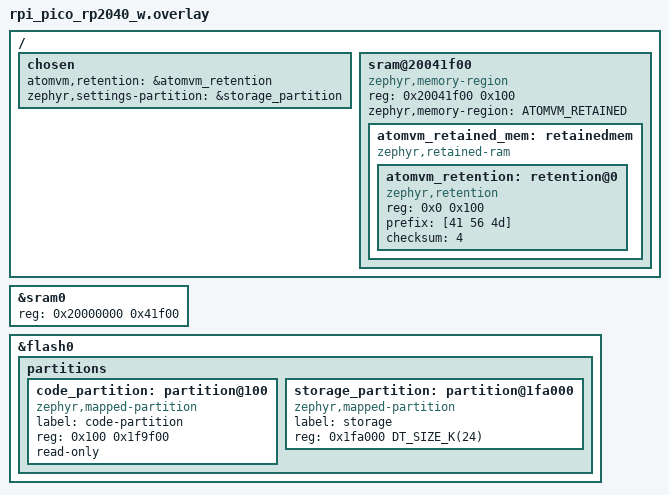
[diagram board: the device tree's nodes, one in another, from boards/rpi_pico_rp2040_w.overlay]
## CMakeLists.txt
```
#
# This file is part of AtomVM.
#
# Copyright 2023 Winford (Uncle Grumpy) <winford@object.stream>
#
# Licensed under the Apache License, Version 2.0 (the "License");
# you may not use this file except in compliance with the License.
# You may obtain a copy of the License at
#
#    http://www.apache.org/licenses/LICENSE-2.0
#
# Unless required by applicable law or agreed to in writing, software
# distributed under the License is distributed on an "AS IS" BASIS,
# WITHOUT WARRANTIES OR CONDITIONS OF ANY KIND, either express or implied.
# See the License for the specific language governing permissions and
# limitations under the License.
#
# SPDX-License-Identifier: Apache-2.0 OR LGPL-2.1-or-later
#

cmake_minimum_required (VERSION 3.20)
set(CMAKE_C_STANDARD_REQUIRED YES)
set(CMAKE_CXX_STANDARD_REQUIRED YES)

# Enforce to disable any compiler-specific extensions
set(CMAKE_C_EXTENSIONS NO)
set(CMAKE_CXX_EXTENSIONS NO)
set(C_STANDARD_REQUIRED YES)
set_property(GLOBAL PROPERTY C_STANDARD_REQUIRED TRUE)
set_property(GLOBAL PROPERTY CSTD iso9899:2011)
set_property(GLOBAL PROPERTY C_STANDARD iso9899:2011)

find_package(Zephyr REQUIRED HINTS $ENV{ZEPHYR_BASE})
project(AtomVM LANGUAGES C)

if (NOT BOARD)
    message(FATAL_ERROR "No BOARD specified for device config generator")
endif ()

list(APPEND CMAKE_MODULE_PATH "${CMAKE_CURRENT_SOURCE_DIR}/../../../CMakeModules")
set(CMAKE_RUNTIME_OUTPUT_DIRECTORY ${CMAKE_BINARY_DIR})

# Options that make sense for this platform
option(AVM_USE_32BIT_FLOAT "Use 32 bit floats." ON)
option(AVM_VERBOSE_ABORT "Print module and line number on VM abort" OFF)
option(AVM_CREATE_STACKTRACES "Create stacktraces" ON)
option(AVM_NEWLIB_NANO "Use 'nano' newlib. Saves 46kB, no `long long` support" OFF)
option(AVM_LOG_DISABLE "Disable log output" OFF)
option(AVM_ENABLE_LOG_COLOR "Use color log output" OFF)
option(AVM_ENABLE_LOG_LINES "Include source and line info for all enabled levels" OFF)
option(AVM_CONFIG_REBOOT_ON_NOT_OK "Reboot when application exits with non 'ok' return" OFF)
option(AVM_DISABLE_GPIO_NIFS "Disable GPIO nifs (input and output)" OFF)
option(AVM_DISABLE_GPIO_PORT_DRIVER "Disable GPIO 'port' driver (input, output, and interrupts)" OFF)

set(AVM_DISABLE_SMP ON CACHE BOOL "Disable SMP" FORCE)
set(AVM_DISABLE_TASK_DRIVER OFF CACHE BOOL "Disable Task Driver" FORCE)
zephyr_library_compile_definitions(AVM_NO_SMP)
add_compile_definitions(AVM_NO_SMP)
add_compile_definitions(AVM_NO_JIT)
add_compile_definitions(_GNU_SOURCE)
add_compile_definitions(_POSIX_C_SOURCE=200809L)
if (NOT AVM_DISABLE_TASK_DRIVER)
    add_compile_definitions(AVM_TASK_DRIVER_ENABLED)
endif()
if (CONFIG_NET_SOCKETS)
    add_compile_definitions(OTP_SOCKET_BSD=1)
endif()

set(HAVE_CLOCK_SETTIME ON FORCE)
set(HAVE_PLATFORM_ATOMIC_H ON CACHE BOOL "Platform has platform_atomic.h" FORCE)
if(CONFIG_SOC_FAMILY_ESPRESSIF_ESP32 AND CONFIG_RISCV)
    # Espressif RISC-V targets such as ESP32-C3 can pass libAtomVM's C11
    # atomic compile check but fail to link __atomic_fetch_* helpers. Use
    # Zephyr's platform atomic shim instead of advertising HAVE_ATOMIC.
    set(ATOMIC_POINTER_LOCK_FREE_IS_TWO FALSE CACHE INTERNAL "Use Zephyr platform atomics" FORCE)
endif()
set(HAVE_RENAME "" CACHE INTERNAL "Have symbol rename" FORCE)

if (AVM_NEWLIB_NANO)
    set(LINKER_FLAGS "${LINKER_FLAGS} -specs=nano.specs")
    set(AVM_LOG_DISABLE ON FORCE)
endif()

if (AVM_CONFIG_REBOOT_ON_NOT_OK)
    add_compile_definitions(CONFIG_REBOOT_ON_NOT_OK)
endif()

# Configure logging
if (AVM_LOG_DISABLE)
    add_compile_definitions(AVM_LOG_DISABLE)
elseif (AVM_LOG_LEVEL_MAX)
    set(AVM_LOG_LEVEL_MAX ${AVM_LOG_LEVEL_MAX} CACHE STRING "AtomVM max log level")
else()
    set(AVM_LOG_LEVEL_MAX LOG_INFO CACHE STRING "AtomVM max log level")
endif()
if (AVM_LOG_LEVEL_MAX)
    set_property(CACHE AVM_LOG_LEVEL_MAX PROPERTY STRINGS LOG_NONE LOG_ERROR LOG_WARN LOG_INFO LOG_DEBUG)
    add_compile_definitions(AVM_LOG_LEVEL_MAX=${AVM_LOG_LEVEL_MAX})
endif()
if (AVM_ENABLE_LOG_COLOR)
    add_compile_definitions(ENABLE_LOG_COLOR)
endif()
if (AVM_ENABLE_LOG_LINES)
    add_compile_definitions(ENABLE_LOG_LINE_INFO)
endif()

# Configure Drivers
if (AVM_DISABLE_GPIO_NIFS)
    add_compile_definitions(AVM_DISABLE_GPIO_NIFS)
endif()
if (AVM_DISABLE_GPIO_PORT_DRIVER)
    add_compile_definitions(AVM_DISABLE_GPIO_PORT_DRIVER)
endif()

## Include additional compilation flags
#include(cmake/compile-flags.cmake)

set(
    PLATFORM_LIB_SUFFIX
    ${CMAKE_SYSTEM_NAME}-${CMAKE_SYSTEM_PROCESSOR}
)

# Specify output executable
target_sources(app PRIVATE src/main.c)
target_include_directories(app PRIVATE
    ${CMAKE_CURRENT_BINARY_DIR}/libAtomVM
    ${CMAKE_BINARY_DIR}/zephyr/include/generated)

add_subdirectory(src/lib)

target_link_libraries(app PRIVATE libAtomVM${PLATFORM_LIB_SUFFIX})

set_property(TARGET app PROPERTY C_STANDARD 11)

if(CMAKE_COMPILER_IS_GNUCC)
    target_compile_options(app PUBLIC -Wall -Wextra -ggdb)
endif()

set(AVM_PORT_ZEPHYR ON CACHE BOOL "Build for Zephyr" FORCE)
set(AVM_DISABLE_JIT ON CACHE BOOL "Disable JIT" FORCE)
add_subdirectory(../../libAtomVM libAtomVM)
target_include_directories(libAtomVM PUBLIC src/lib)
add_dependencies(libAtomVM zephyr_generated_headers)
add_dependencies(libAtomVM${PLATFORM_LIB_SUFFIX} zephyr_generated_headers)
target_link_libraries(app PUBLIC libAtomVM)

message("----------------------------------------")
message(STATUS "Board       : ${BOARD}")
message("--------Device Configuration Info-------")
message(STATUS "Clock Hz    : ${CONFIG_SYS_CLOCK_HW_CYCLES_PER_SEC}")
message(STATUS "Flash Size  : ${CONFIG_FLASH_SIZE}K")
```

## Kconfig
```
#
# Copyright 2026 Peter M <petermm@gmail.com>
#
# SPDX-License-Identifier: Apache-2.0 OR LGPL-2.1-or-later
#

mainmenu "AtomVM Zephyr Configuration"

source "$(APPLICATION_SOURCE_DIR)/Kconfig.atomvm"
source "Kconfig.zephyr"
```

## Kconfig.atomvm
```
#
# Copyright 2026 Peter M <petermm@gmail.com>
#
# SPDX-License-Identifier: Apache-2.0 OR LGPL-2.1-or-later
#

menu "AtomVM Settings"

config AVM_ENABLE_WIFI
    bool "Enable Wi-Fi and Networking support"
    default y if SOC_WIFI_SUPPORTED
    default n
    imply NETWORKING
    imply NET_L2_ETHERNET
    imply NET_IPV4
    imply NET_DHCPV4
    imply DNS_RESOLVER
    imply NET_TCP
    imply NET_UDP
    imply NET_SOCKETS
    imply SNTP
    imply NET_SOCKETS_SERVICE
    imply NET_CONNECTION_MANAGER
    imply WIFI
    imply NET_L2_WIFI_MGMT
    imply NET_MGMT
    imply NET_MGMT_EVENT
    imply NET_MGMT_EVENT_INFO
    imply EVENTFD
    imply ZVFS
    help
      Enable WiFi networking and socket support in AtomVM.

config AVM_ENABLE_CRYPTO
    bool "Enable Crypto support (MBEDTLS/PSA)"
    default y
    imply MBEDTLS
    imply PSA_CRYPTO
    imply MBEDTLS_HASH_ALL_ENABLED
    imply MBEDTLS_CIPHER_ALL_ENABLED
    imply MBEDTLS_CIPHER
    imply PSA_WANT_ALG_CFB
    imply PSA_WANT_ALG_ECB_NO_PADDING
    imply MBEDTLS_CTR_DRBG_C
    imply MBEDTLS_SSL_PROTO_TLS1_2 if NETWORKING
    imply MBEDTLS_SSL_PROTO_TLS1_3 if NETWORKING
    imply MBEDTLS_SSL_TLS1_3_KEY_EXCHANGE_MODE_EPHEMERAL_ENABLED if NETWORKING
    imply MBEDTLS_SSL_TLS1_3_KEY_EXCHANGE_MODE_PSK_ENABLED if NETWORKING
    imply MBEDTLS_KEY_EXCHANGE_ECDHE_ECDSA_ENABLED if NETWORKING
    imply MBEDTLS_KEY_EXCHANGE_PSK_ENABLED if NETWORKING
    imply MBEDTLS_SSL_SERVER_NAME_INDICATION if NETWORKING
    imply MBEDTLS_X509_CRT_PARSE_C if NETWORKING
    imply MBEDTLS_HAVE_TIME_DATE if NETWORKING
    imply PSA_WANT_ALG_ECDH
    imply PSA_WANT_ALG_ECDSA
    imply PSA_WANT_KEY_TYPE_ECC_KEY_PAIR_IMPORT
    imply PSA_WANT_ECC_SECP_R1_256
    help
      Enable mbedTLS and PSA Cryptography support for AtomVM.

endmenu

# Override defaults of Zephyr options when AVM_ENABLE_WIFI is active
config NET_SOCKETS_SERVICE_STACK_SIZE
    default 3072 if AVM_ENABLE_WIFI

config ZVFS_EVENTFD_MAX
    default 4 if AVM_ENABLE_WIFI

config ZVFS_POLL_MAX
    default 8 if AVM_ENABLE_WIFI
```

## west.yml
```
# Copyright (c) 2021 Nordic Semiconductor ASA
# SPDX-License-Identifier: Apache-2.0

manifest:
  remotes:
    - name: zephyrproject-rtos
      url-base: https://github.com/zephyrproject-rtos
  defaults:
    remote: zephyrproject-rtos
  projects:
    - name: zephyr
      remote: zephyrproject-rtos
      revision: v4.5.0
      import:
        # By using name-allowlist we can clone only the modules that are
        # strictly needed by the application.
        name-allowlist:
          - cmsis          # required by the ARM port
          - cmsis_6        # required by the ARM port in newer Zephyr
          - hal_espressif  # required by ESP32 boards
          - hal_infineon   # required by Raspberry Pi Pico W Wi-Fi
          - hal_stm32      # required by STM32 boards
          - hal_rpi_pico   # required by Raspberry Pi Pico (RP2040) boards
          - mbedtls        # required for ESP32 crypto/WiFi
          - tf-psa-crypto  # required for newer Zephyr PSA crypto
          - native_sim     # 32-bit native
          - native_sim_64  # 64-bit native
          - qemu_x86       # QEMU 32-bit virtual machine
          - qemu_x86_64    # QEMU 64-bit virtual machine
          - fatfs          # required for FAT filesystem support
  self:
    path: .
```

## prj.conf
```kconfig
#
# This file is part of AtomVM.
#
# Copyright 2023 Winford (Uncle Grumpy) <winford@object.stream>
#
# Licensed under the Apache License, Version 2.0 (the "License");
# you may not use this file except in compliance with the License.
# You may obtain a copy of the License at
#
#    http://www.apache.org/licenses/LICENSE-2.0
#
# Unless required by applicable law or agreed to in writing, software
# distributed under the License is distributed on an "AS IS" BASIS,
# WITHOUT WARRANTIES OR CONDITIONS OF ANY KIND, either express or implied.
# See the License for the specific language governing permissions and
# limitations under the License.
#
# SPDX-License-Identifier: Apache-2.0 OR LGPL-2.1-or-later
#

CONFIG_KERNEL_BIN_NAME="AtomVM"
CONFIG_MAIN_STACK_SIZE=16384
CONFIG_STDOUT_CONSOLE=y
CONFIG_CONSOLE_SUBSYS=y
CONFIG_SYS_HEAP_AUTO=y
CONFIG_GPIO=y
CONFIG_POSIX_SYSTEM_INTERFACES=y
CONFIG_POSIX_TIMERS=y
CONFIG_CBPRINTF_FP_SUPPORT=y
CONFIG_REBOOT=y
CONFIG_STACK_USAGE=y
CONFIG_RUNTIME_ERROR_CHECKS=y
CONFIG_OUTPUT_PRINT_MEMORY_USAGE=y
CONFIG_FORTIFY_SOURCE_RUN_TIME=y

# I2C
CONFIG_I2C=y

# Power management and task watchdog APIs are part of the standard Zephyr
# platform surface. The custom policy remains idle unless an application
# explicitly forces a state through the Zephyr API.
CONFIG_PM=y
CONFIG_PM_POLICY_CUSTOM=y
CONFIG_TASK_WDT=y
CONFIG_TASK_WDT_HW_FALLBACK=n

# AtomVM relies on GNU-style constructors for registration/initialization
CONFIG_STATIC_INIT_GNU=y

# POSIX API is required globally for standard POSIX functions and native_sim builds
CONFIG_POSIX_API=y
```

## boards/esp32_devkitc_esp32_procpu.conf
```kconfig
CONFIG_RETAINED_MEM=y
CONFIG_RETENTION=y
CONFIG_ADC=y
CONFIG_SPI=y
CONFIG_PWM=y
CONFIG_FLASH=y
CONFIG_FLASH_MAP=y
CONFIG_NVS=y
CONFIG_SETTINGS=y
CONFIG_SETTINGS_NVS=y
CONFIG_MPU_ALLOW_FLASH_WRITE=y
```

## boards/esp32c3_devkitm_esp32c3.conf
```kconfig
CONFIG_POWEROFF=y
CONFIG_WIFI_USAGE_MODE_STA_AP=y
CONFIG_WIFI_NM=y
CONFIG_NET_IF_MAX_IPV4_COUNT=2
CONFIG_NET_IF_MAX_IPV6_COUNT=2
CONFIG_NET_DHCPV4_SERVER=y
CONFIG_NET_DHCPV4_SERVER_ADDR_COUNT=4
CONFIG_NET_DHCPV4_SERVER_ICMP_PROBE_TIMEOUT=0
CONFIG_ZVFS_POLL_MAX=8
CONFIG_ZVFS_EVENTFD_MAX=4
CONFIG_RETAINED_MEM=y
CONFIG_RETENTION=y
CONFIG_ADC=y
CONFIG_SPI=y
CONFIG_PWM=y
CONFIG_FLASH=y
CONFIG_FLASH_MAP=y
CONFIG_FLASH_MAP_LABELS=y
CONFIG_NVS=y
CONFIG_SETTINGS=y
CONFIG_SETTINGS_NVS=y
CONFIG_MPU_ALLOW_FLASH_WRITE=y
```

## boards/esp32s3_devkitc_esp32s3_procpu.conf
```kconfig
CONFIG_POWEROFF=y
CONFIG_WIFI_USAGE_MODE_STA_AP=y
CONFIG_WIFI_NM=y
CONFIG_NET_IF_MAX_IPV4_COUNT=2
CONFIG_NET_IF_MAX_IPV6_COUNT=2
CONFIG_NET_DHCPV4_SERVER=y
CONFIG_NET_DHCPV4_SERVER_ADDR_COUNT=4
CONFIG_NET_DHCPV4_SERVER_ICMP_PROBE_TIMEOUT=0
CONFIG_ZVFS_POLL_MAX=8
CONFIG_ZVFS_EVENTFD_MAX=4
CONFIG_RETAINED_MEM=y
CONFIG_RETENTION=y
CONFIG_ADC=y
CONFIG_SPI=y
CONFIG_PWM=y
CONFIG_FLASH=y
CONFIG_FLASH_MAP=y
CONFIG_NVS=y
CONFIG_SETTINGS=y
CONFIG_SETTINGS_NVS=y
CONFIG_MPU_ALLOW_FLASH_WRITE=y
```

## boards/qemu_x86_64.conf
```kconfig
#
# This file is part of AtomVM.
#
# Copyright 2026 Peter M <petermm@gmail.com>
#
# SPDX-License-Identifier: Apache-2.0 OR LGPL-2.1-or-later
#

# qemu_x86_64 enables CONFIG_SMP and CONFIG_MP_MAX_NUM_CPUS=2 in Zephyr's
# board defconfig. Keep the SMP settings explicit here so this board remains
# the Zephyr target that exercises AtomVM's experimental SMP path.
CONFIG_SMP=y
CONFIG_MP_MAX_NUM_CPUS=2

# The Zephyr SMP shim uses kernel threads and custom thread data to distinguish
# secondary scheduler threads from the main scheduler. qemu_x86_64 uses two
# CPUs, so one pre-allocated dynamic stack is enough for the secondary
# scheduler thread.
CONFIG_DYNAMIC_THREAD=y
CONFIG_DYNAMIC_THREAD_STACK_SIZE=16384
CONFIG_DYNAMIC_THREAD_POOL_SIZE=1
CONFIG_THREAD_CUSTOM_DATA=y
```

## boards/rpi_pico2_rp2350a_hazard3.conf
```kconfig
#
# This file is part of AtomVM.
#
# Copyright 2026 Peter M <petermm@gmail.com>
#
# Licensed under the Apache License, Version 2.0 (the "License");
# you may not use this file except in compliance with the License.
# You may obtain a copy of the License at
#
#    http://www.apache.org/licenses/LICENSE-2.0
#
# Unless required by applicable law or agreed to in writing, software
# distributed under the License is distributed on an "AS IS" BASIS,
# WITHOUT WARRANTIES OR CONDITIONS OF ANY KIND, either express or implied.
# See the License for the specific language governing permissions and
# limitations under the License.
#
# SPDX-License-Identifier: Apache-2.0 OR LGPL-2.1-or-later
#

# Raspberry Pi Pico 2 (RP2350A Hazard3 RISC-V) non-W board fragment.
#
# Zephyr exposes this as the qualified rpi_pico2/rp2350a/hazard3 board. The
# plain Pico 2 has no networking hardware, so the networking/Wi-Fi options
# forced on by the base prj.conf are explicitly unset here.

# No networking hardware on the plain Pico 2.
# CONFIG_NETWORKING is not set
# CONFIG_NET_L2_ETHERNET is not set
# CONFIG_NET_IPV4 is not set
# CONFIG_NET_DHCPV4 is not set
# CONFIG_DNS_RESOLVER is not set
# CONFIG_NET_TCP is not set
# CONFIG_NET_UDP is not set
# CONFIG_NET_SOCKETS is not set
# CONFIG_POSIX_API is not set
# CONFIG_NET_CONNECTION_MANAGER is not set
# CONFIG_WIFI is not set
# CONFIG_NET_L2_WIFI_MGMT is not set
# CONFIG_NET_MGMT is not set
# CONFIG_NET_MGMT_EVENT is not set
# CONFIG_NET_MGMT_EVENT_INFO is not set
# CONFIG_EVENTFD is not set
# CONFIG_ZVFS_EVENTFD_MAX is not set
```

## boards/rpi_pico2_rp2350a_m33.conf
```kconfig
#
# This file is part of AtomVM.
#
# Copyright 2026 Peter M <petermm@gmail.com>
#
# Licensed under the Apache License, Version 2.0 (the "License");
# you may not use this file except in compliance with the License.
# You may obtain a copy of the License at
#
#    http://www.apache.org/licenses/LICENSE-2.0
#
# Unless required by applicable law or agreed to in writing, software
# distributed under the License is distributed on an "AS IS" BASIS,
# WITHOUT WARRANTIES OR CONDITIONS OF ANY KIND, either express or implied.
# See the License for the specific language governing permissions and
# limitations under the License.
#
# SPDX-License-Identifier: Apache-2.0 OR LGPL-2.1-or-later
#

# Raspberry Pi Pico 2 (RP2350A Cortex-M33) non-W board fragment.
#
# The plain Pico 2 has no networking hardware, so the networking/Wi-Fi options
# forced on by the base prj.conf are explicitly unset here.

# No networking hardware on the plain Pico 2.
# CONFIG_NETWORKING is not set
# CONFIG_NET_L2_ETHERNET is not set
# CONFIG_NET_IPV4 is not set
# CONFIG_NET_DHCPV4 is not set
# CONFIG_DNS_RESOLVER is not set
# CONFIG_NET_TCP is not set
# CONFIG_NET_UDP is not set
# CONFIG_NET_SOCKETS is not set
# CONFIG_POSIX_API is not set
# CONFIG_NET_CONNECTION_MANAGER is not set
# CONFIG_WIFI is not set
# CONFIG_NET_L2_WIFI_MGMT is not set
# CONFIG_NET_MGMT is not set
# CONFIG_NET_MGMT_EVENT is not set
# CONFIG_NET_MGMT_EVENT_INFO is not set
# CONFIG_EVENTFD is not set
# CONFIG_ZVFS_EVENTFD_MAX is not set
```

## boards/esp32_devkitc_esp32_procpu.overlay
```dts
/ {
	chosen {
		atomvm,retention = &atomvm_retention;
		atomvm,dac = &dac;
		zephyr,settings-partition = &storage_partition;
	};

	memory@50001f00 {
		compatible = "zephyr,memory-region", "mmio-sram";
		reg = <0x50001f00 0x100>;
		ranges = <0x0 0x50001f00 0x100>;
		zephyr,memory-region = "ATOMVM_RTC_RETAINED";
		status = "okay";
		#address-cells = <1>;
		#size-cells = <1>;

		atomvm_retained_mem: retainedmem {
			compatible = "zephyr,retained-ram";
			status = "okay";
			ranges;
			#address-cells = <1>;
			#size-cells = <1>;

			atomvm_retention: retention@0 {
				compatible = "zephyr,retention";
				status = "okay";
				reg = <0x0 0x100>;
				prefix = [41 56 4d];
				checksum = <4>;
			};
		};
	};

	wifi_ap: wifi_ap {
		compatible = "espressif,esp32-wifi";
		status = "okay";
	};
};

&rtc_slow_ram {
	reg = <0x50000000 0x1f00>;
};

&dac {
	status = "okay";
	#address-cells = <1>;
	#size-cells = <0>;

	channel@0 {
		reg = <0>;
		zephyr,resolution = <8>;
	};
};
```

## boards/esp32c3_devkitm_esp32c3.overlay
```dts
/*
 * Keep the Zephyr and AtomVM console on the ESP32-C3 native USB
 * Serial/JTAG port used for flashing and monitoring.
 */

/ {
	chosen {
		atomvm,retention = &atomvm_retention;
		zephyr,console = &usb_serial;
		zephyr,shell-uart = &usb_serial;
	};

	memory@50001f00 {
		compatible = "zephyr,memory-region", "mmio-sram";
		reg = <0x50001f00 0x100>;
		ranges = <0x0 0x50001f00 0x100>;
		zephyr,memory-region = "ATOMVM_RTC_RETAINED";
		status = "okay";
		#address-cells = <1>;
		#size-cells = <1>;
		atomvm_retained_mem: retainedmem {
			compatible = "zephyr,retained-ram";
			status = "okay";
			ranges;
			#address-cells = <1>;
			#size-cells = <1>;
			atomvm_retention: retention@0 {
				compatible = "zephyr,retention";
				status = "okay";
				reg = <0x0 0x100>;
				prefix = [41 56 4d];
				checksum = <4>;
			};
		};
	};
};

&rtc_fast_ram {
	reg = <0x50000000 0x1f00>;
};
```

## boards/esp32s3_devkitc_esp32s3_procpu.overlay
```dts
/*
 * Keep the Zephyr and AtomVM console on the ESP32-S3 native USB
 * Serial/JTAG port used for flashing and monitoring.
 */

/ {
	chosen {
		atomvm,retention = &atomvm_retention;
		zephyr,console = &usb_serial;
		zephyr,shell-uart = &usb_serial;
		zephyr,settings-partition = &storage_partition;
	};

	wifi_ap: wifi_ap {
		compatible = "espressif,esp32-wifi";
		status = "okay";
	};

	memory@50001f00 {
		compatible = "zephyr,memory-region", "mmio-sram";
		reg = <0x50001f00 0x100>;
		ranges = <0x0 0x50001f00 0x100>;
		zephyr,memory-region = "ATOMVM_RTC_RETAINED";
		status = "okay";
		#address-cells = <1>;
		#size-cells = <1>;
		atomvm_retained_mem: retainedmem {
			compatible = "zephyr,retained-ram";
			status = "okay";
			ranges;
			#address-cells = <1>;
			#size-cells = <1>;
			atomvm_retention: retention@0 {
				compatible = "zephyr,retention";
				status = "okay";
				reg = <0x0 0x100>;
				prefix = [41 56 4d];
				checksum = <4>;
			};
		};
	};
};

&usb_serial {
	status = "okay";
};

&rtc_slow_ram {
	reg = <0x50000000 0x1f00>;
};
```

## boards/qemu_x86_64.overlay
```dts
/*
 * Keep QEMU's RAM size within the virtual address space configured by the
 * board. This also prevents CONFIG_SYS_HEAP_AUTO from sizing the libc arena
 * from QEMU's larger physical-memory default.
 */
&dram0 {
	reg = <0x0 0x7fff00>;
};
```

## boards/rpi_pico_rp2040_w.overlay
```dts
/ {
	chosen {
		atomvm,retention = &atomvm_retention;
		zephyr,settings-partition = &storage_partition;
	};
	sram@20041f00 {
		compatible = "zephyr,memory-region", "mmio-sram";
		reg = <0x20041f00 0x100>;
		ranges = <0x0 0x20041f00 0x100>;
		zephyr,memory-region = "ATOMVM_RETAINED";
		status = "okay";
		#address-cells = <1>;
		#size-cells = <1>;
		atomvm_retained_mem: retainedmem {
			compatible = "zephyr,retained-ram";
			status = "okay";
			ranges;
			#address-cells = <1>;
			#size-cells = <1>;
			atomvm_retention: retention@0 {
				compatible = "zephyr,retention";
				status = "okay";
				reg = <0x0 0x100>;
				prefix = [41 56 4d];
				checksum = <4>;
			};
		};
	};
};

&sram0 {
	reg = <0x20000000 0x41f00>;
};

&flash0 {
	partitions {
		#address-cells = <1>;
		#size-cells = <1>;

		/delete-node/ partition@100;

		code_partition: partition@100 {
			compatible = "zephyr,mapped-partition";
			label = "code-partition";
			reg = <0x100 0x1f9f00>;
			read-only;
		};

		storage_partition: partition@1fa000 {
			compatible = "zephyr,mapped-partition";
			label = "storage";
			reg = <0x1fa000 DT_SIZE_K(24)>;
		};
	};
};
```

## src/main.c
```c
/*
 * This file is part of AtomVM.
 *
 * Copyright 2023 Winford (Uncle Grumpy) <winford@object.stream>
 *
 * Licensed under the Apache License, Version 2.0 (the "License");
 * you may not use this file except in compliance with the License.
 * You may obtain a copy of the License at
 *
 *    http://www.apache.org/licenses/LICENSE-2.0
 *
 * Unless required by applicable law or agreed to in writing, software
 * distributed under the License is distributed on an "AS IS" BASIS,
 * WITHOUT WARRANTIES OR CONDITIONS OF ANY KIND, either express or implied.
 * See the License for the specific language governing permissions and
 * limitations under the License.
 *
 * SPDX-License-Identifier: Apache-2.0 OR LGPL-2.1-or-later
 */

#include <errno.h>
#include <signal.h>
#include <stddef.h>
#include <stdint.h>
#include <stdio.h>
#include <unistd.h>

#include <zephyr/kernel.h>
#include <zephyr/sys/reboot.h>

#if defined(CONFIG_SOC_FAMILY_ESPRESSIF_ESP32)
#include <spi_flash_mmap.h>
#endif

#include <avm_version.h>
#include <avmpack.h>
#include <context.h>
#include <defaultatoms.h>
#include <globalcontext.h>
#include <module.h>
#include <smp.h>
#include <utils.h>

#include "lib/avm_devcfg.h"
#include "lib/avm_log.h"
#include "lib/zephyros_sys.h"

#define AVM_ADDRESS (AVM_APP_ADDRESS)
#define AVM_FLASH_END (CFG_FLASH_END)

#define TAG "AtomVM"

#define ATOMVM_BANNER                                                   \
    "\n"                                                                \
    "    ###########################################################\n" \
    "\n"                                                                \
    "       ###    ########  #######  ##     ## ##     ## ##     ## \n" \
    "      ## ##      ##    ##     ## ###   ### ##     ## ###   ### \n" \
    "     ##   ##     ##    ##     ## #### #### ##     ## #### #### \n" \
    "    ##     ##    ##    ##     ## ## ### ## ##     ## ## ### ## \n" \
    "    #########    ##    ##     ## ##     ##  ##   ##  ##     ## \n" \
    "    ##     ##    ##    ##     ## ##     ##   ## ##   ##     ## \n" \
    "    ##     ##    ##     #######  ##     ##    ###    ##     ## \n" \
    "\n"                                                                \
    "    ###########################################################\n" \
    "\n"

#if defined(AVM_ZEPHYR_TEST_AVM)
extern const uint8_t zephyr_test_modules_avm[];
extern const size_t zephyr_test_modules_avm_size;
#endif

int main()
{
    printk("%s", ATOMVM_BANNER);

    GlobalContext *glb = globalcontext_new();

    AVM_LOGI(TAG, "Starting AtomVM revision %s", ATOMVM_VERSION);

#if defined(AVM_ZEPHYR_BOOT_TEST)
#ifndef AVM_NO_SMP
    AVM_LOGI(TAG, "Zephyr boot test: SMP schedulers=%d online=%d", smp_get_online_processors(), glb->online_schedulers);
#else
    AVM_LOGI(TAG, "Zephyr boot test: SMP disabled");
#endif
    globalcontext_destroy(glb);
    return 0;
#endif

    uint32_t size = (AVM_FLASH_END - AVM_ADDRESS);
    const void *flashed_avm;

#if defined(AVM_ZEPHYR_TEST_AVM)
    flashed_avm = zephyr_test_modules_avm;
    size = (uint32_t) zephyr_test_modules_avm_size;
#elif defined(CONFIG_SOC_FAMILY_ESPRESSIF_ESP32)
    spi_flash_mmap_handle_t avm_mmap_handle;
    esp_err_t mmap_result = spi_flash_mmap(AVM_ADDRESS, size, SPI_FLASH_MMAP_DATA, &flashed_avm, &avm_mmap_handle);
    if (mmap_result != ESP_OK) {
        AVM_LOGE(TAG, "Unable to map application AVM pack from flash offset 0x%lx: %d", (unsigned long) AVM_ADDRESS, mmap_result);
        AVM_ABORT();
    }
#else
    flashed_avm = (const void *) AVM_ADDRESS;
#endif

    uint32_t startup_beam_size;
    const void *startup_beam;
    const char *startup_module_name;

    AVM_LOGD(TAG, "Maximum application size: %lu KiB", (unsigned long) (size / 1024));

    port_driver_init_all(glb);
    nif_collection_init_all(glb);

    if (!avmpack_is_valid(flashed_avm, size) || !avmpack_find_section_by_flag(flashed_avm, size, BEAM_START_FLAG, BEAM_START_FLAG, &startup_beam, &startup_beam_size, &startup_module_name)) {
        AVM_LOGE(TAG, "Invalid AVM Pack");
        AVM_ABORT();
    }
    AVM_LOGD(TAG, "Booting file mapped at: %p, size: %lu", flashed_avm, (unsigned long) startup_beam_size);
    AVM_LOGI(TAG, "Application size: %lu B, free flash space: %lu KiB", (unsigned long) startup_beam_size, (unsigned long) ((size - startup_beam_size) / 1024));

    struct ConstAVMPack *avmpack_data = malloc(sizeof(struct ConstAVMPack));
    if (IS_NULL_PTR(avmpack_data)) {
        AVM_LOGE(TAG, "Memory error: Cannot allocate AVMPackData.");
        AVM_ABORT();
    }
    avmpack_data_init(&avmpack_data->base, &const_avm_pack_info, size);
    avmpack_data->base.data = flashed_avm;
    avmpack_data->base.in_use = true;
    synclist_append(&glb->avmpack_data, &avmpack_data->base.avmpack_head);

    Module *mod = module_new_from_iff_binary(glb, startup_beam, startup_beam_size);
    globalcontext_insert_module(glb, mod);
    Context *ctx = context_new(glb);
    ctx->leader = 1;

    printk("Starting: %s...\n", startup_module_name);
    printk("---\n");

    context_execute_loop(ctx, mod, "start", 0);

    term ret_value = ctx->x[0];
    char *ret_atom_string = interop_atom_to_string(ctx, ret_value);
    if (ret_atom_string != NULL) {
        AVM_LOGI(TAG, "Exited with return: %s", ret_atom_string);
    } else {
        AVM_LOGI(TAG, "Exited with return value: %lx", (long) term_to_int32(ret_value));
    }
    free(ret_atom_string);

#if defined(AVM_ZEPHYR_TEST_EXIT)
    if (ret_value == OK_ATOM) {
        AVM_LOGI(TAG, "AtomVM test application terminated successfully.");
        return 0;
    }
    AVM_LOGE(TAG, "AtomVM test application terminated with non-ok return value.");
    return 1;
#else
    bool reboot_on_not_ok =
#if defined(CONFIG_REBOOT_ON_NOT_OK)
        CONFIG_REBOOT_ON_NOT_OK ? true : false;
#else
        false;
#endif
    if (reboot_on_not_ok && ret_value != OK_ATOM) {
        AVM_LOGE(TAG, "AtomVM application terminated with non-ok return value.  Rebooting ...");
        sys_reboot(SYS_REBOOT_COLD);
    } else {
        AVM_LOGI(TAG, "AtomVM application terminated.  Going to sleep forever ...");
        while (1) {
            ;
        }
    }
#endif
    return 0;
}
```
